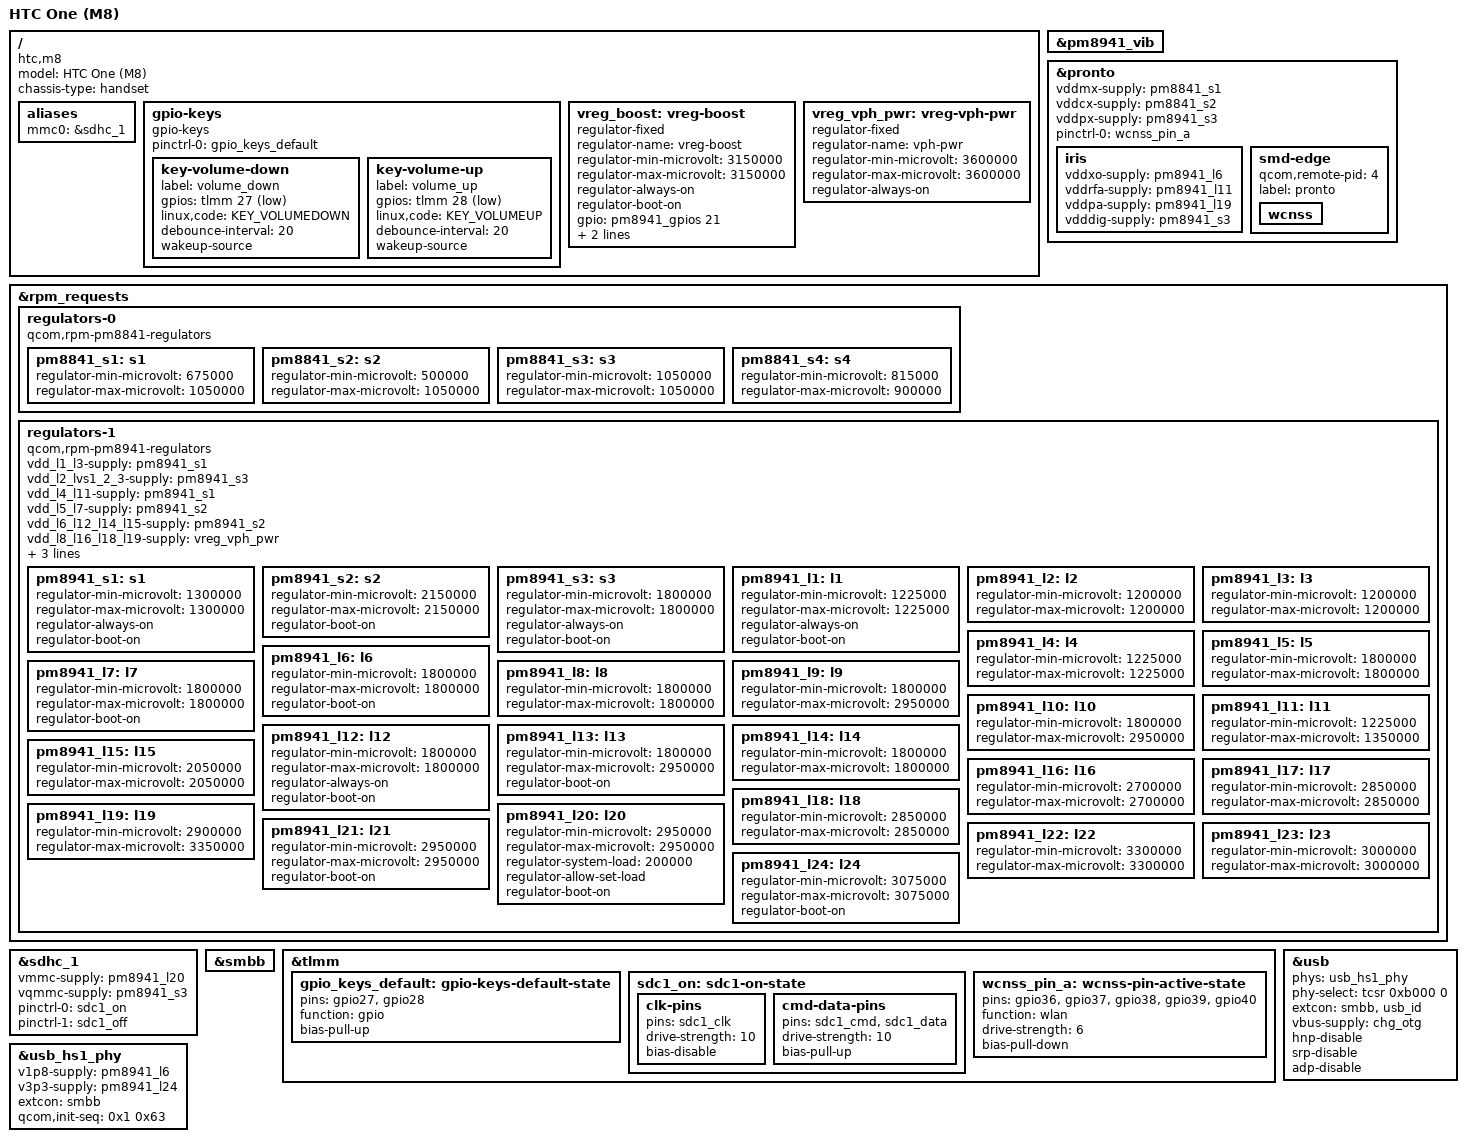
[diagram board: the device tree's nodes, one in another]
// SPDX-License-Identifier: GPL-2.0-only
#include "qcom-msm8974pro.dtsi"
#include "pm8841.dtsi"
#include "pm8941.dtsi"
#include <dt-bindings/input/input.h>

/ {
	model = "HTC One (M8)";
	compatible = "htc,m8", "qcom,msm8974pro", "qcom,msm8974";
	chassis-type = "handset";

	aliases {
		mmc0 = &sdhc_1;
	};

	gpio-keys {
		compatible = "gpio-keys";

		pinctrl-0 = <&gpio_keys_default>;
		pinctrl-names = "default";

		key-volume-down {
			label = "volume_down";
			gpios = <&tlmm 27 GPIO_ACTIVE_LOW>;
			linux,code = <KEY_VOLUMEDOWN>;
			debounce-interval = <20>;
			wakeup-source;
		};

		key-volume-up {
			label = "volume_up";
			gpios = <&tlmm 28 GPIO_ACTIVE_LOW>;
			linux,code = <KEY_VOLUMEUP>;
			debounce-interval = <20>;
			wakeup-source;
		};
	};

	vreg_boost: vreg-boost {
		compatible = "regulator-fixed";

		regulator-name = "vreg-boost";
		regulator-min-microvolt = <3150000>;
		regulator-max-microvolt = <3150000>;

		regulator-always-on;
		regulator-boot-on;

		gpio = <&pm8941_gpios 21 GPIO_ACTIVE_HIGH>;
		enable-active-high;

		pinctrl-0 = <&boost_bypass_n_pin>;
		pinctrl-names = "default";
	};

	vreg_vph_pwr: vreg-vph-pwr {
		compatible = "regulator-fixed";
		regulator-name = "vph-pwr";

		regulator-min-microvolt = <3600000>;
		regulator-max-microvolt = <3600000>;

		regulator-always-on;
	};
};

&pm8941_vib {
	status = "okay";
};

&pronto {
	vddmx-supply = <&pm8841_s1>;
	vddcx-supply = <&pm8841_s2>;
	vddpx-supply = <&pm8941_s3>;

	pinctrl-0 = <&wcnss_pin_a>;
	pinctrl-names = "default";

	status = "okay";

	iris {
		vddxo-supply = <&pm8941_l6>;
		vddrfa-supply = <&pm8941_l11>;
		vddpa-supply = <&pm8941_l19>;
		vdddig-supply = <&pm8941_s3>;
	};

	smd-edge {
		qcom,remote-pid = <4>;
		label = "pronto";

		wcnss {
			status = "okay";
		};
	};
};

&rpm_requests {
	regulators-0 {
		compatible = "qcom,rpm-pm8841-regulators";

		pm8841_s1: s1 {
			regulator-min-microvolt = <675000>;
			regulator-max-microvolt = <1050000>;
		};

		pm8841_s2: s2 {
			regulator-min-microvolt = <500000>;
			regulator-max-microvolt = <1050000>;
		};

		pm8841_s3: s3 {
			regulator-min-microvolt = <1050000>;
			regulator-max-microvolt = <1050000>;
		};

		pm8841_s4: s4 {
			regulator-min-microvolt = <815000>;
			regulator-max-microvolt = <900000>;
		};
	};

	regulators-1 {
		compatible = "qcom,rpm-pm8941-regulators";

		vdd_l1_l3-supply = <&pm8941_s1>;
		vdd_l2_lvs1_2_3-supply = <&pm8941_s3>;
		vdd_l4_l11-supply = <&pm8941_s1>;
		vdd_l5_l7-supply = <&pm8941_s2>;
		vdd_l6_l12_l14_l15-supply = <&pm8941_s2>;
		vdd_l8_l16_l18_l19-supply = <&vreg_vph_pwr>;
		vdd_l9_l10_l17_l22-supply = <&vreg_boost>;
		vdd_l13_l20_l23_l24-supply = <&vreg_boost>;
		vdd_l21-supply = <&vreg_boost>;

		pm8941_s1: s1 {
			regulator-min-microvolt = <1300000>;
			regulator-max-microvolt = <1300000>;
			regulator-always-on;
			regulator-boot-on;
		};

		pm8941_s2: s2 {
			regulator-min-microvolt = <2150000>;
			regulator-max-microvolt = <2150000>;
			regulator-boot-on;
		};

		pm8941_s3: s3 {
			regulator-min-microvolt = <1800000>;
			regulator-max-microvolt = <1800000>;
			regulator-always-on;
			regulator-boot-on;
		};

		pm8941_l1: l1 {
			regulator-min-microvolt = <1225000>;
			regulator-max-microvolt = <1225000>;
			regulator-always-on;
			regulator-boot-on;
		};

		pm8941_l2: l2 {
			regulator-min-microvolt = <1200000>;
			regulator-max-microvolt = <1200000>;
		};

		pm8941_l3: l3 {
			regulator-min-microvolt = <1200000>;
			regulator-max-microvolt = <1200000>;
		};

		pm8941_l4: l4 {
			regulator-min-microvolt = <1225000>;
			regulator-max-microvolt = <1225000>;
		};

		pm8941_l5: l5 {
			regulator-min-microvolt = <1800000>;
			regulator-max-microvolt = <1800000>;
		};

		pm8941_l6: l6 {
			regulator-min-microvolt = <1800000>;
			regulator-max-microvolt = <1800000>;
			regulator-boot-on;
		};

		pm8941_l7: l7 {
			regulator-min-microvolt = <1800000>;
			regulator-max-microvolt = <1800000>;
			regulator-boot-on;
		};

		pm8941_l8: l8 {
			regulator-min-microvolt = <1800000>;
			regulator-max-microvolt = <1800000>;
		};

		pm8941_l9: l9 {
			regulator-min-microvolt = <1800000>;
			regulator-max-microvolt = <2950000>;
		};

		pm8941_l10: l10 {
			regulator-min-microvolt = <1800000>;
			regulator-max-microvolt = <2950000>;
		};

		pm8941_l11: l11 {
			regulator-min-microvolt = <1225000>;
			regulator-max-microvolt = <1350000>;
		};

		pm8941_l12: l12 {
			regulator-min-microvolt = <1800000>;
			regulator-max-microvolt = <1800000>;
			regulator-always-on;
			regulator-boot-on;
		};

		pm8941_l13: l13 {
			regulator-min-microvolt = <1800000>;
			regulator-max-microvolt = <2950000>;
			regulator-boot-on;
		};

		pm8941_l14: l14 {
			regulator-min-microvolt = <1800000>;
			regulator-max-microvolt = <1800000>;
		};

		pm8941_l15: l15 {
			regulator-min-microvolt = <2050000>;
			regulator-max-microvolt = <2050000>;
		};

		pm8941_l16: l16 {
			regulator-min-microvolt = <2700000>;
			regulator-max-microvolt = <2700000>;
		};

		pm8941_l17: l17 {
			regulator-min-microvolt = <2850000>;
			regulator-max-microvolt = <2850000>;
		};

		pm8941_l18: l18 {
			regulator-min-microvolt = <2850000>;
			regulator-max-microvolt = <2850000>;
		};

		pm8941_l19: l19 {
			regulator-min-microvolt = <2900000>;
			regulator-max-microvolt = <3350000>;
		};

		pm8941_l20: l20 {
			regulator-min-microvolt = <2950000>;
			regulator-max-microvolt = <2950000>;
			regulator-system-load = <200000>;
			regulator-allow-set-load;
			regulator-boot-on;
		};

		pm8941_l21: l21 {
			regulator-min-microvolt = <2950000>;
			regulator-max-microvolt = <2950000>;
			regulator-boot-on;
		};

		pm8941_l22: l22 {
			regulator-min-microvolt = <3300000>;
			regulator-max-microvolt = <3300000>;
		};

		pm8941_l23: l23 {
			regulator-min-microvolt = <3000000>;
			regulator-max-microvolt = <3000000>;
		};

		pm8941_l24: l24 {
			regulator-min-microvolt = <3075000>;
			regulator-max-microvolt = <3075000>;
			regulator-boot-on;
		};
	};
};

&sdhc_1 {
	vmmc-supply = <&pm8941_l20>;
	vqmmc-supply = <&pm8941_s3>;

	pinctrl-0 = <&sdc1_on>;
	pinctrl-1 = <&sdc1_off>;
	pinctrl-names = "default", "sleep";

	status = "okay";
};

&smbb {
	status = "okay";
};

&tlmm {
	gpio_keys_default: gpio-keys-default-state {
		pins = "gpio27", "gpio28";
		function = "gpio";
		bias-pull-up;
	};

	sdc1_on: sdc1-on-state {
		clk-pins {
			pins = "sdc1_clk";
			drive-strength = <10>;
			bias-disable;
		};

		cmd-data-pins {
			pins = "sdc1_cmd", "sdc1_data";
			drive-strength = <10>;
			bias-pull-up;
		};
	};

	wcnss_pin_a: wcnss-pin-active-state {
		pins = "gpio36", "gpio37", "gpio38", "gpio39", "gpio40";
		function = "wlan";
		drive-strength = <6>;
		bias-pull-down;
	};
};

&usb {
	phys = <&usb_hs1_phy>;
	phy-select = <&tcsr 0xb000 0>;
	extcon = <&smbb>, <&usb_id>;
	vbus-supply = <&chg_otg>;

	hnp-disable;
	srp-disable;
	adp-disable;

	status = "okay";
};

&usb_hs1_phy {
	v1p8-supply = <&pm8941_l6>;
	v3p3-supply = <&pm8941_l24>;
	extcon = <&smbb>;
	qcom,init-seq = /bits/ 8 <0x1 0x63>;
	status = "okay";
};
